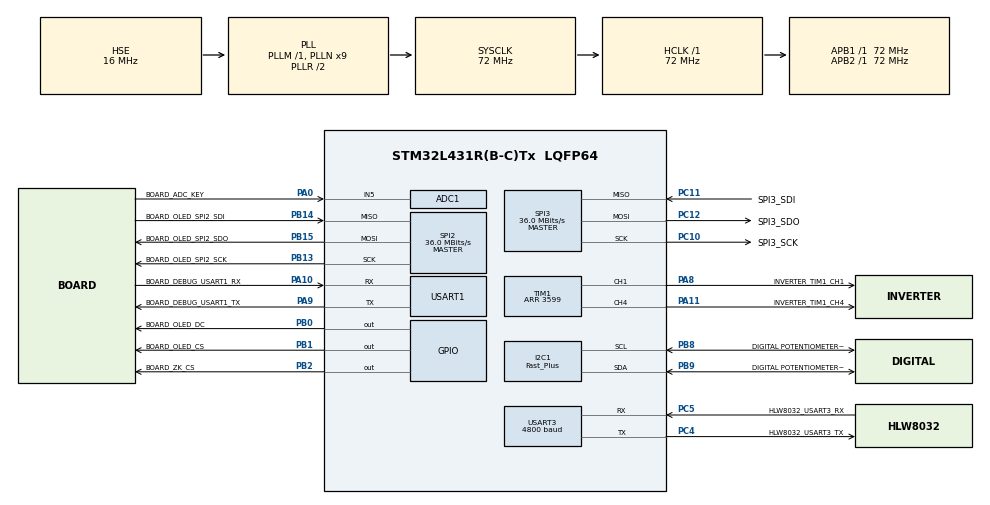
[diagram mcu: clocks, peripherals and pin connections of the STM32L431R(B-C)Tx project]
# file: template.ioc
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ADC1.Channel-0\#ChannelRegularConversion=ADC_CHANNEL_5
ADC1.NbrOfConversionFlag=1
ADC1.OffsetNumber-0\#ChannelRegularConversion=ADC_OFFSET_NONE
ADC1.Rank-0\#ChannelRegularConversion=1
ADC1.SamplingTime-0\#ChannelRegularConversion=ADC_SAMPLETIME_2CYCLES_5
ADC1.master=1
Dma.Request0=USART1_RX
Dma.Request1=USART1_TX
Dma.Request2=USART3_RX
Dma.Request3=USART3_TX
Dma.USART1_RX.0.Direction=DMA_PERIPH_TO_MEMORY
Dma.USART1_RX.0.Instance=DMA2_Channel7
Dma.USART1_RX.0.MemDataAlignment=DMA_MDATAALIGN_BYTE
Dma.USART1_RX.0.MemInc=DMA_MINC_ENABLE
Dma.USART1_RX.0.Mode=DMA_NORMAL
Dma.USART1_RX.0.PeriphDataAlignment=DMA_PDATAALIGN_BYTE
Dma.USART1_RX.0.PeriphInc=DMA_PINC_DISABLE
Dma.USART1_RX.0.Priority=DMA_PRIORITY_LOW
Dma.USART1_TX.1.Direction=DMA_MEMORY_TO_PERIPH
Dma.USART1_TX.1.Instance=DMA2_Channel6
Dma.USART1_TX.1.MemDataAlignment=DMA_MDATAALIGN_BYTE
Dma.USART1_TX.1.MemInc=DMA_MINC_ENABLE
Dma.USART1_TX.1.Mode=DMA_NORMAL
Dma.USART1_TX.1.PeriphDataAlignment=DMA_PDATAALIGN_BYTE
Dma.USART1_TX.1.PeriphInc=DMA_PINC_DISABLE
Dma.USART1_TX.1.Priority=DMA_PRIORITY_LOW
Dma.USART3_RX.2.Direction=DMA_PERIPH_TO_MEMORY
Dma.USART3_RX.2.Instance=DMA1_Channel3
Dma.USART3_RX.2.MemDataAlignment=DMA_MDATAALIGN_BYTE
Dma.USART3_RX.2.MemInc=DMA_MINC_ENABLE
Dma.USART3_RX.2.Mode=DMA_NORMAL
Dma.USART3_RX.2.PeriphDataAlignment=DMA_PDATAALIGN_BYTE
Dma.USART3_RX.2.PeriphInc=DMA_PINC_DISABLE
Dma.USART3_RX.2.Priority=DMA_PRIORITY_LOW
Dma.USART3_TX.3.Direction=DMA_MEMORY_TO_PERIPH
Dma.USART3_TX.3.Instance=DMA1_Channel2
Dma.USART3_TX.3.MemDataAlignment=DMA_MDATAALIGN_BYTE
Dma.USART3_TX.3.MemInc=DMA_MINC_ENABLE
Dma.USART3_TX.3.Mode=DMA_NORMAL
Dma.USART3_TX.3.PeriphDataAlignment=DMA_PDATAALIGN_BYTE
Dma.USART3_TX.3.PeriphInc=DMA_PINC_DISABLE
Dma.USART3_TX.3.Priority=DMA_PRIORITY_LOW
I2C1.I2C_Speed_Mode=I2C_Fast_Plus
I2C1.Timing=0x00300D2E
Mcu.Family=STM32L4
Mcu.Name=STM32L431R(B-C)Tx
Mcu.Package=LQFP64
NVIC.ADC1_IRQn=true\:2\:3\:true\:false\:true\:true\:true\:true
NVIC.DMA1_Channel2_IRQn=true\:1\:1\:true\:false\:true\:false\:true\:true
NVIC.DMA1_Channel3_IRQn=true\:1\:1\:true\:false\:true\:false\:true\:true
NVIC.DMA2_Channel6_IRQn=true\:2\:2\:true\:false\:true\:false\:true\:true
NVIC.DMA2_Channel7_IRQn=true\:2\:2\:true\:false\:true\:false\:true\:true
NVIC.PriorityGroup=NVIC_PRIORITYGROUP_2
NVIC.TIM1_UP_TIM16_IRQn=true\:1\:0\:true\:false\:true\:true\:true\:true
NVIC.TIM6_DAC_IRQn=true\:3\:0\:true\:false\:true\:true\:true\:true
NVIC.USART1_IRQn=true\:2\:2\:true\:false\:true\:true\:true\:true
NVIC.USART3_IRQn=true\:1\:1\:true\:false\:true\:true\:true\:true
PA0.GPIO_Label=BOARD_ADC_KEY
PA0.Signal=ADCx_IN5
PA10.GPIO_Label=BOARD_DEBUG_USART1_RX
PA10.Mode=Asynchronous
PA10.Signal=USART1_RX
PA11.GPIO_Label=INVERTER_TIM1_CH4
PA11.Signal=S_TIM1_CH4
PA13\ (JTMS-SWDIO).Mode=Serial_Wire
PA13\ (JTMS-SWDIO).Signal=SYS_JTMS-SWDIO
PA14\ (JTCK-SWCLK).Mode=Serial_Wire
PA14\ (JTCK-SWCLK).Signal=SYS_JTCK-SWCLK
PA8.GPIO_Label=INVERTER_TIM1_CH1
PA8.Signal=S_TIM1_CH1
PA9.GPIO_Label=BOARD_DEBUG_USART1_TX
PA9.Mode=Asynchronous
PA9.Signal=USART1_TX
PB0.GPIO_Label=BOARD_OLED_DC
PB0.GPIO_Speed=GPIO_SPEED_FREQ_HIGH
PB0.Signal=GPIO_Output
PB1.GPIO_Label=BOARD_OLED_CS
PB1.GPIO_Speed=GPIO_SPEED_FREQ_HIGH
PB1.PinState=GPIO_PIN_SET
PB1.Signal=GPIO_Output
PB13.GPIO_Label=BOARD_OLED_SPI2_SCK
PB13.Mode=Full_Duplex_Master
PB13.Signal=SPI2_SCK
PB14.GPIO_Label=BOARD_OLED_SPI2_SDI
PB14.Mode=Full_Duplex_Master
PB14.Signal=SPI2_MISO
PB15.GPIO_Label=BOARD_OLED_SPI2_SDO
PB15.Mode=Full_Duplex_Master
PB15.Signal=SPI2_MOSI
PB2.GPIO_Label=BOARD_ZK_CS
PB2.GPIO_Speed=GPIO_SPEED_FREQ_HIGH
PB2.PinState=GPIO_PIN_SET
PB2.Signal=GPIO_Output
PB8.GPIO_Label=DIGITAL POTENTIOMETER_I2C1_SCL
PB8.Mode=I2C
PB8.Signal=I2C1_SCL
PB9.GPIO_Label=DIGITAL POTENTIOMETER_I2C1_SDA
PB9.Mode=I2C
PB9.Signal=I2C1_SDA
PC10.GPIO_Label=SPI3_SCK
PC10.Mode=Full_Duplex_Master
PC10.Signal=SPI3_SCK
PC11.GPIO_Label=SPI3_SDI
PC11.Mode=Full_Duplex_Master
PC11.Signal=SPI3_MISO
PC12.GPIO_Label=SPI3_SDO
PC12.Mode=Full_Duplex_Master
PC12.Signal=SPI3_MOSI
PC4.GPIO_Label=HLW8032_USART3_TX
PC4.Mode=Asynchronous
PC4.Signal=USART3_TX
PC5.GPIO_Label=HLW8032_USART3_RX
PC5.Mode=Asynchronous
PC5.Signal=USART3_RX
PH0-OSC_IN\ (PH0).Mode=HSE-External-Oscillator
PH0-OSC_IN\ (PH0).Signal=RCC_OSC_IN
PH1-OSC_OUT\ (PH1).Mode=HSE-External-Oscillator
PH1-OSC_OUT\ (PH1).Signal=RCC_OSC_OUT
ProjectManager.HeapSize=0x200
ProjectManager.StackSize=0x400
ProjectManager.TargetToolchain=MDK-ARM V5.32
RCC.ADCFreq_Value=64000000
RCC.AHBFreq_Value=72000000
RCC.APB1Freq_Value=72000000
RCC.APB1TimFreq_Value=72000000
RCC.APB2Freq_Value=72000000
RCC.APB2TimFreq_Value=72000000
RCC.CortexFreq_Value=72000000
RCC.HCLKFreq_Value=72000000
RCC.HSE_VALUE=16000000
RCC.HSI48_VALUE=48000000
RCC.HSI_VALUE=16000000
RCC.LSE_VALUE=32768
RCC.MSI_VALUE=4000000
RCC.PLLN=9
RCC.PLLSourceVirtual=RCC_PLLSOURCE_HSE
RCC.SYSCLKFreq_VALUE=72000000
RCC.SYSCLKSource=RCC_SYSCLKSOURCE_PLLCLK
RCC.VCOOutputFreq_Value=144000000
SH.ADCx_IN5.0=ADC1_IN5,IN5-Single-Ended
SH.S_TIM1_CH1.0=TIM1_CH1,PWM Generation1 CH1
SH.S_TIM1_CH4.0=TIM1_CH4,PWM Generation4 CH4
SPI2.CalculateBaudRate=36.0 MBits/s
SPI2.DataSize=SPI_DATASIZE_8BIT
SPI2.Direction=SPI_DIRECTION_2LINES
SPI2.Mode=SPI_MODE_MASTER
SPI2.VirtualType=VM_MASTER
SPI3.CalculateBaudRate=36.0 MBits/s
SPI3.DataSize=SPI_DATASIZE_8BIT
SPI3.Direction=SPI_DIRECTION_2LINES
SPI3.Mode=SPI_MODE_MASTER
SPI3.VirtualType=VM_MASTER
TIM1.AutoReloadPreload=TIM_AUTORELOAD_PRELOAD_ENABLE
TIM1.Channel-PWM\ Generation1\ CH1=TIM_CHANNEL_1
TIM1.Channel-PWM\ Generation2\ CH2N=TIM_CHANNEL_2
TIM1.Channel-PWM\ Generation4\ CH4=TIM_CHANNEL_4
TIM1.Period=3599
TIM6.AutoReloadPreload=TIM_AUTORELOAD_PRELOAD_ENABLE
TIM6.Period=999
TIM6.Prescaler=71
USART1.VirtualMode-Asynchronous=VM_ASYNC
USART3.BaudRate=4800
USART3.VirtualMode-Asynchronous=VM_ASYNC
VP_TIM6_VS_ClockSourceINT.Mode=Enable_Timer
board=custom

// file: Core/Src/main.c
/* USER CODE BEGIN Header */
/**
  ******************************************************************************
  * @file           : main.c
  * @brief          : Main program body
  ******************************************************************************
  * @attention
  *
  * Copyright (c) 2022 STMicroelectronics.
  * All rights reserved.
  *
  * This software is licensed under terms that can be found in the LICENSE file
  * in the root directory of this software component.
  * If no LICENSE file comes with this software, it is provided AS-IS.
  *
  ******************************************************************************
  */
/* USER CODE END Header */
#include "main.h"
#include "adc.h"
#include "dma.h"
#include "i2c.h"
#include "spi.h"
#include "tim.h"
#include "usart.h"
#include "gpio.h"

/* USER CODE BEGIN Includes */
#include "mytask.h"
#include "hlw8032.h"
#include "inverter.h"

/* USER CODE END Includes */

void SystemClock_Config(void);

int main(void)
{

  /* MCU Configuration--------------------------------------------------------*/

  /* Reset of all peripherals, Initializes the Flash interface and the Systick. */
  HAL_Init();

  /* Configure the system clock */
  SystemClock_Config();

  /* Initialize all configured peripherals */
  MX_GPIO_Init();
  MX_DMA_Init();
  MX_SPI2_Init();
  MX_USART1_UART_Init();
  MX_ADC1_Init();
  MX_TIM6_Init();
  MX_USART3_UART_Init();
  MX_TIM1_Init();
  MX_I2C1_Init();
  MX_SPI3_Init();
  /* USER CODE BEGIN 2 */
  INVERTER_Init();
  extern uint16_t inverterNum;
  int32_t i = 0;
  volatile float fps1 = 0, fps3 = 0;

  /* USER CODE END 2 */

  /* Infinite loop */
  while (1)
  {

    /* USER CODE BEGIN 3 */
    DEBUG_SYSTEM_Task();
    HLW8032_OLED_Task(inverterNum);

    i = i==100000 ? 0 : i+1;
  }
  /* USER CODE END 3 */
}

void SystemClock_Config(void)
{
  RCC_OscInitTypeDef RCC_OscInitStruct = {0};
  RCC_ClkInitTypeDef RCC_ClkInitStruct = {0};

  /** Configure the main internal regulator output voltage
  */
  if (HAL_PWREx_ControlVoltageScaling(PWR_REGULATOR_VOLTAGE_SCALE1) != HAL_OK)
  {
    Error_Handler();
  }
  /** Initializes the RCC Oscillators according to the specified parameters
  * in the RCC_OscInitTypeDef structure.
  */
  RCC_OscInitStruct.OscillatorType = RCC_OSCILLATORTYPE_HSE;
  RCC_OscInitStruct.HSEState = RCC_HSE_ON;
  RCC_OscInitStruct.PLL.PLLState = RCC_PLL_ON;
  RCC_OscInitStruct.PLL.PLLSource = RCC_PLLSOURCE_HSE;
  RCC_OscInitStruct.PLL.PLLM = 1;
  RCC_OscInitStruct.PLL.PLLN = 9;
  RCC_OscInitStruct.PLL.PLLP = RCC_PLLP_DIV7;
  RCC_OscInitStruct.PLL.PLLQ = RCC_PLLQ_DIV2;
  RCC_OscInitStruct.PLL.PLLR = RCC_PLLR_DIV2;
  if (HAL_RCC_OscConfig(&RCC_OscInitStruct) != HAL_OK)
  {
    Error_Handler();
  }
  /** Initializes the CPU, AHB and APB buses clocks
  */
  RCC_ClkInitStruct.ClockType = RCC_CLOCKTYPE_HCLK|RCC_CLOCKTYPE_SYSCLK
                              |RCC_CLOCKTYPE_PCLK1|RCC_CLOCKTYPE_PCLK2;
  RCC_ClkInitStruct.SYSCLKSource = RCC_SYSCLKSOURCE_PLLCLK;
  RCC_ClkInitStruct.AHBCLKDivider = RCC_SYSCLK_DIV1;
  RCC_ClkInitStruct.APB1CLKDivider = RCC_HCLK_DIV1;
  RCC_ClkInitStruct.APB2CLKDivider = RCC_HCLK_DIV1;

  if (HAL_RCC_ClockConfig(&RCC_ClkInitStruct, FLASH_LATENCY_4) != HAL_OK)
  {
    Error_Handler();
  }
}

void Error_Handler(void)
{
  __disable_irq();
  while (1)
  {
  }
}
